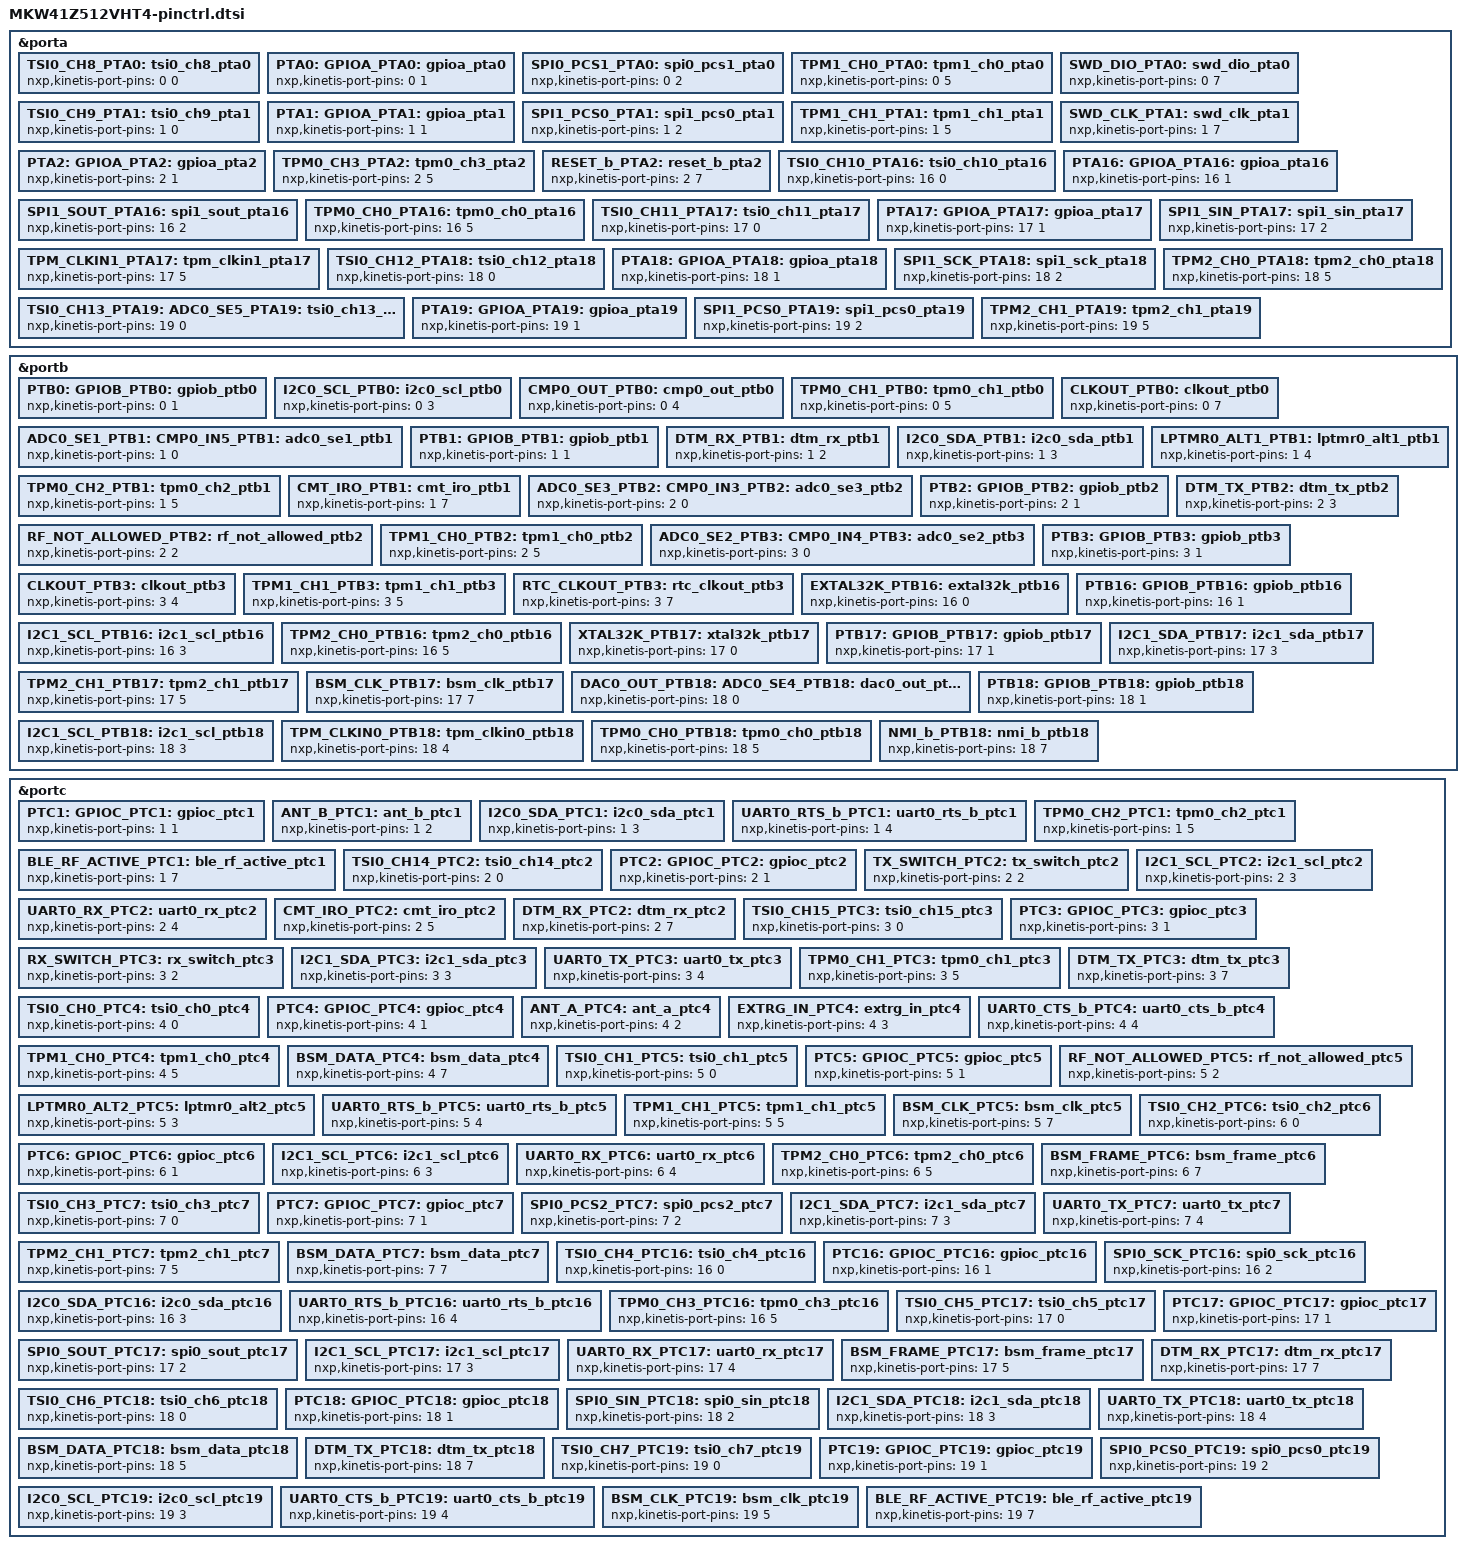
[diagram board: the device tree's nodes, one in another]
/*
 * NOTE: Autogenerated file by kinetis_signal2dts.py
 *       for MKW41Z512VHT4/signal_configuration.xml
 *
 * SPDX-License-Identifier: Apache-2.0
 */

/*
 * Pin nodes are of the form:
 *
 *	<SIGNAL[0..n]>: <signal[0]> {
 *		nxp,kinetis-port-pins = < PIN PCR[MUX] >;
 *	};
 */

&porta {
	TSI0_CH8_PTA0: tsi0_ch8_pta0 {
		nxp,kinetis-port-pins = < 0 0 >;
	};
	PTA0: GPIOA_PTA0: gpioa_pta0 {
		nxp,kinetis-port-pins = < 0 1 >;
	};
	SPI0_PCS1_PTA0: spi0_pcs1_pta0 {
		nxp,kinetis-port-pins = < 0 2 >;
	};
	TPM1_CH0_PTA0: tpm1_ch0_pta0 {
		nxp,kinetis-port-pins = < 0 5 >;
	};
	SWD_DIO_PTA0: swd_dio_pta0 {
		nxp,kinetis-port-pins = < 0 7 >;
	};
	TSI0_CH9_PTA1: tsi0_ch9_pta1 {
		nxp,kinetis-port-pins = < 1 0 >;
	};
	PTA1: GPIOA_PTA1: gpioa_pta1 {
		nxp,kinetis-port-pins = < 1 1 >;
	};
	SPI1_PCS0_PTA1: spi1_pcs0_pta1 {
		nxp,kinetis-port-pins = < 1 2 >;
	};
	TPM1_CH1_PTA1: tpm1_ch1_pta1 {
		nxp,kinetis-port-pins = < 1 5 >;
	};
	SWD_CLK_PTA1: swd_clk_pta1 {
		nxp,kinetis-port-pins = < 1 7 >;
	};
	PTA2: GPIOA_PTA2: gpioa_pta2 {
		nxp,kinetis-port-pins = < 2 1 >;
	};
	TPM0_CH3_PTA2: tpm0_ch3_pta2 {
		nxp,kinetis-port-pins = < 2 5 >;
	};
	RESET_b_PTA2: reset_b_pta2 {
		nxp,kinetis-port-pins = < 2 7 >;
	};
	TSI0_CH10_PTA16: tsi0_ch10_pta16 {
		nxp,kinetis-port-pins = < 16 0 >;
	};
	PTA16: GPIOA_PTA16: LLWU_P4_PTA16: gpioa_pta16 {
		nxp,kinetis-port-pins = < 16 1 >;
	};
	SPI1_SOUT_PTA16: spi1_sout_pta16 {
		nxp,kinetis-port-pins = < 16 2 >;
	};
	TPM0_CH0_PTA16: tpm0_ch0_pta16 {
		nxp,kinetis-port-pins = < 16 5 >;
	};
	TSI0_CH11_PTA17: tsi0_ch11_pta17 {
		nxp,kinetis-port-pins = < 17 0 >;
	};
	PTA17: GPIOA_PTA17: LLWU_P5_PTA17: RF_RESET_PTA17: gpioa_pta17 {
		nxp,kinetis-port-pins = < 17 1 >;
	};
	SPI1_SIN_PTA17: spi1_sin_pta17 {
		nxp,kinetis-port-pins = < 17 2 >;
	};
	TPM_CLKIN1_PTA17: tpm_clkin1_pta17 {
		nxp,kinetis-port-pins = < 17 5 >;
	};
	TSI0_CH12_PTA18: tsi0_ch12_pta18 {
		nxp,kinetis-port-pins = < 18 0 >;
	};
	PTA18: GPIOA_PTA18: LLWU_P6_PTA18: gpioa_pta18 {
		nxp,kinetis-port-pins = < 18 1 >;
	};
	SPI1_SCK_PTA18: spi1_sck_pta18 {
		nxp,kinetis-port-pins = < 18 2 >;
	};
	TPM2_CH0_PTA18: tpm2_ch0_pta18 {
		nxp,kinetis-port-pins = < 18 5 >;
	};
	TSI0_CH13_PTA19: ADC0_SE5_PTA19: tsi0_ch13_pta19 {
		nxp,kinetis-port-pins = < 19 0 >;
	};
	PTA19: GPIOA_PTA19: LLWU_P7_PTA19: gpioa_pta19 {
		nxp,kinetis-port-pins = < 19 1 >;
	};
	SPI1_PCS0_PTA19: spi1_pcs0_pta19 {
		nxp,kinetis-port-pins = < 19 2 >;
	};
	TPM2_CH1_PTA19: tpm2_ch1_pta19 {
		nxp,kinetis-port-pins = < 19 5 >;
	};
};

&portb {
	PTB0: GPIOB_PTB0: LLWU_P8_PTB0: XTAL_OUT_EN_PTB0: gpiob_ptb0 {
		nxp,kinetis-port-pins = < 0 1 >;
	};
	I2C0_SCL_PTB0: i2c0_scl_ptb0 {
		nxp,kinetis-port-pins = < 0 3 >;
	};
	CMP0_OUT_PTB0: cmp0_out_ptb0 {
		nxp,kinetis-port-pins = < 0 4 >;
	};
	TPM0_CH1_PTB0: tpm0_ch1_ptb0 {
		nxp,kinetis-port-pins = < 0 5 >;
	};
	CLKOUT_PTB0: clkout_ptb0 {
		nxp,kinetis-port-pins = < 0 7 >;
	};
	ADC0_SE1_PTB1: CMP0_IN5_PTB1: adc0_se1_ptb1 {
		nxp,kinetis-port-pins = < 1 0 >;
	};
	PTB1: GPIOB_PTB1: gpiob_ptb1 {
		nxp,kinetis-port-pins = < 1 1 >;
	};
	DTM_RX_PTB1: dtm_rx_ptb1 {
		nxp,kinetis-port-pins = < 1 2 >;
	};
	I2C0_SDA_PTB1: i2c0_sda_ptb1 {
		nxp,kinetis-port-pins = < 1 3 >;
	};
	LPTMR0_ALT1_PTB1: lptmr0_alt1_ptb1 {
		nxp,kinetis-port-pins = < 1 4 >;
	};
	TPM0_CH2_PTB1: tpm0_ch2_ptb1 {
		nxp,kinetis-port-pins = < 1 5 >;
	};
	CMT_IRO_PTB1: cmt_iro_ptb1 {
		nxp,kinetis-port-pins = < 1 7 >;
	};
	ADC0_SE3_PTB2: CMP0_IN3_PTB2: adc0_se3_ptb2 {
		nxp,kinetis-port-pins = < 2 0 >;
	};
	PTB2: GPIOB_PTB2: gpiob_ptb2 {
		nxp,kinetis-port-pins = < 2 1 >;
	};
	RF_NOT_ALLOWED_PTB2: rf_not_allowed_ptb2 {
		nxp,kinetis-port-pins = < 2 2 >;
	};
	DTM_TX_PTB2: dtm_tx_ptb2 {
		nxp,kinetis-port-pins = < 2 3 >;
	};
	TPM1_CH0_PTB2: tpm1_ch0_ptb2 {
		nxp,kinetis-port-pins = < 2 5 >;
	};
	ADC0_SE2_PTB3: CMP0_IN4_PTB3: adc0_se2_ptb3 {
		nxp,kinetis-port-pins = < 3 0 >;
	};
	PTB3: GPIOB_PTB3: gpiob_ptb3 {
		nxp,kinetis-port-pins = < 3 1 >;
	};
	CLKOUT_PTB3: clkout_ptb3 {
		nxp,kinetis-port-pins = < 3 4 >;
	};
	TPM1_CH1_PTB3: tpm1_ch1_ptb3 {
		nxp,kinetis-port-pins = < 3 5 >;
	};
	RTC_CLKOUT_PTB3: rtc_clkout_ptb3 {
		nxp,kinetis-port-pins = < 3 7 >;
	};
	EXTAL32K_PTB16: extal32k_ptb16 {
		nxp,kinetis-port-pins = < 16 0 >;
	};
	PTB16: GPIOB_PTB16: gpiob_ptb16 {
		nxp,kinetis-port-pins = < 16 1 >;
	};
	I2C1_SCL_PTB16: i2c1_scl_ptb16 {
		nxp,kinetis-port-pins = < 16 3 >;
	};
	TPM2_CH0_PTB16: tpm2_ch0_ptb16 {
		nxp,kinetis-port-pins = < 16 5 >;
	};
	XTAL32K_PTB17: xtal32k_ptb17 {
		nxp,kinetis-port-pins = < 17 0 >;
	};
	PTB17: GPIOB_PTB17: gpiob_ptb17 {
		nxp,kinetis-port-pins = < 17 1 >;
	};
	I2C1_SDA_PTB17: i2c1_sda_ptb17 {
		nxp,kinetis-port-pins = < 17 3 >;
	};
	TPM2_CH1_PTB17: tpm2_ch1_ptb17 {
		nxp,kinetis-port-pins = < 17 5 >;
	};
	BSM_CLK_PTB17: bsm_clk_ptb17 {
		nxp,kinetis-port-pins = < 17 7 >;
	};
	DAC0_OUT_PTB18: ADC0_SE4_PTB18: CMP0_IN2_PTB18: dac0_out_ptb18 {
		nxp,kinetis-port-pins = < 18 0 >;
	};
	PTB18: GPIOB_PTB18: gpiob_ptb18 {
		nxp,kinetis-port-pins = < 18 1 >;
	};
	I2C1_SCL_PTB18: i2c1_scl_ptb18 {
		nxp,kinetis-port-pins = < 18 3 >;
	};
	TPM_CLKIN0_PTB18: tpm_clkin0_ptb18 {
		nxp,kinetis-port-pins = < 18 4 >;
	};
	TPM0_CH0_PTB18: tpm0_ch0_ptb18 {
		nxp,kinetis-port-pins = < 18 5 >;
	};
	NMI_b_PTB18: nmi_b_ptb18 {
		nxp,kinetis-port-pins = < 18 7 >;
	};
};

&portc {
	PTC1: GPIOC_PTC1: gpioc_ptc1 {
		nxp,kinetis-port-pins = < 1 1 >;
	};
	ANT_B_PTC1: ant_b_ptc1 {
		nxp,kinetis-port-pins = < 1 2 >;
	};
	I2C0_SDA_PTC1: i2c0_sda_ptc1 {
		nxp,kinetis-port-pins = < 1 3 >;
	};
	UART0_RTS_b_PTC1: uart0_rts_b_ptc1 {
		nxp,kinetis-port-pins = < 1 4 >;
	};
	TPM0_CH2_PTC1: tpm0_ch2_ptc1 {
		nxp,kinetis-port-pins = < 1 5 >;
	};
	BLE_RF_ACTIVE_PTC1: ble_rf_active_ptc1 {
		nxp,kinetis-port-pins = < 1 7 >;
	};
	TSI0_CH14_PTC2: tsi0_ch14_ptc2 {
		nxp,kinetis-port-pins = < 2 0 >;
	};
	PTC2: GPIOC_PTC2: LLWU_P10_PTC2: gpioc_ptc2 {
		nxp,kinetis-port-pins = < 2 1 >;
	};
	TX_SWITCH_PTC2: tx_switch_ptc2 {
		nxp,kinetis-port-pins = < 2 2 >;
	};
	I2C1_SCL_PTC2: i2c1_scl_ptc2 {
		nxp,kinetis-port-pins = < 2 3 >;
	};
	UART0_RX_PTC2: uart0_rx_ptc2 {
		nxp,kinetis-port-pins = < 2 4 >;
	};
	CMT_IRO_PTC2: cmt_iro_ptc2 {
		nxp,kinetis-port-pins = < 2 5 >;
	};
	DTM_RX_PTC2: dtm_rx_ptc2 {
		nxp,kinetis-port-pins = < 2 7 >;
	};
	TSI0_CH15_PTC3: tsi0_ch15_ptc3 {
		nxp,kinetis-port-pins = < 3 0 >;
	};
	PTC3: GPIOC_PTC3: LLWU_P11_PTC3: gpioc_ptc3 {
		nxp,kinetis-port-pins = < 3 1 >;
	};
	RX_SWITCH_PTC3: rx_switch_ptc3 {
		nxp,kinetis-port-pins = < 3 2 >;
	};
	I2C1_SDA_PTC3: i2c1_sda_ptc3 {
		nxp,kinetis-port-pins = < 3 3 >;
	};
	UART0_TX_PTC3: uart0_tx_ptc3 {
		nxp,kinetis-port-pins = < 3 4 >;
	};
	TPM0_CH1_PTC3: tpm0_ch1_ptc3 {
		nxp,kinetis-port-pins = < 3 5 >;
	};
	DTM_TX_PTC3: dtm_tx_ptc3 {
		nxp,kinetis-port-pins = < 3 7 >;
	};
	TSI0_CH0_PTC4: tsi0_ch0_ptc4 {
		nxp,kinetis-port-pins = < 4 0 >;
	};
	PTC4: GPIOC_PTC4: LLWU_P12_PTC4: gpioc_ptc4 {
		nxp,kinetis-port-pins = < 4 1 >;
	};
	ANT_A_PTC4: ant_a_ptc4 {
		nxp,kinetis-port-pins = < 4 2 >;
	};
	EXTRG_IN_PTC4: extrg_in_ptc4 {
		nxp,kinetis-port-pins = < 4 3 >;
	};
	UART0_CTS_b_PTC4: uart0_cts_b_ptc4 {
		nxp,kinetis-port-pins = < 4 4 >;
	};
	TPM1_CH0_PTC4: tpm1_ch0_ptc4 {
		nxp,kinetis-port-pins = < 4 5 >;
	};
	BSM_DATA_PTC4: bsm_data_ptc4 {
		nxp,kinetis-port-pins = < 4 7 >;
	};
	TSI0_CH1_PTC5: tsi0_ch1_ptc5 {
		nxp,kinetis-port-pins = < 5 0 >;
	};
	PTC5: GPIOC_PTC5: LLWU_P13_PTC5: gpioc_ptc5 {
		nxp,kinetis-port-pins = < 5 1 >;
	};
	RF_NOT_ALLOWED_PTC5: rf_not_allowed_ptc5 {
		nxp,kinetis-port-pins = < 5 2 >;
	};
	LPTMR0_ALT2_PTC5: lptmr0_alt2_ptc5 {
		nxp,kinetis-port-pins = < 5 3 >;
	};
	UART0_RTS_b_PTC5: uart0_rts_b_ptc5 {
		nxp,kinetis-port-pins = < 5 4 >;
	};
	TPM1_CH1_PTC5: tpm1_ch1_ptc5 {
		nxp,kinetis-port-pins = < 5 5 >;
	};
	BSM_CLK_PTC5: bsm_clk_ptc5 {
		nxp,kinetis-port-pins = < 5 7 >;
	};
	TSI0_CH2_PTC6: tsi0_ch2_ptc6 {
		nxp,kinetis-port-pins = < 6 0 >;
	};
	PTC6: GPIOC_PTC6: LLWU_P14_PTC6: XTAL_OUT_EN_PTC6: gpioc_ptc6 {
		nxp,kinetis-port-pins = < 6 1 >;
	};
	I2C1_SCL_PTC6: i2c1_scl_ptc6 {
		nxp,kinetis-port-pins = < 6 3 >;
	};
	UART0_RX_PTC6: uart0_rx_ptc6 {
		nxp,kinetis-port-pins = < 6 4 >;
	};
	TPM2_CH0_PTC6: tpm2_ch0_ptc6 {
		nxp,kinetis-port-pins = < 6 5 >;
	};
	BSM_FRAME_PTC6: bsm_frame_ptc6 {
		nxp,kinetis-port-pins = < 6 7 >;
	};
	TSI0_CH3_PTC7: tsi0_ch3_ptc7 {
		nxp,kinetis-port-pins = < 7 0 >;
	};
	PTC7: GPIOC_PTC7: LLWU_P15_PTC7: gpioc_ptc7 {
		nxp,kinetis-port-pins = < 7 1 >;
	};
	SPI0_PCS2_PTC7: spi0_pcs2_ptc7 {
		nxp,kinetis-port-pins = < 7 2 >;
	};
	I2C1_SDA_PTC7: i2c1_sda_ptc7 {
		nxp,kinetis-port-pins = < 7 3 >;
	};
	UART0_TX_PTC7: uart0_tx_ptc7 {
		nxp,kinetis-port-pins = < 7 4 >;
	};
	TPM2_CH1_PTC7: tpm2_ch1_ptc7 {
		nxp,kinetis-port-pins = < 7 5 >;
	};
	BSM_DATA_PTC7: bsm_data_ptc7 {
		nxp,kinetis-port-pins = < 7 7 >;
	};
	TSI0_CH4_PTC16: tsi0_ch4_ptc16 {
		nxp,kinetis-port-pins = < 16 0 >;
	};
	PTC16: GPIOC_PTC16: LLWU_P0_PTC16: gpioc_ptc16 {
		nxp,kinetis-port-pins = < 16 1 >;
	};
	SPI0_SCK_PTC16: spi0_sck_ptc16 {
		nxp,kinetis-port-pins = < 16 2 >;
	};
	I2C0_SDA_PTC16: i2c0_sda_ptc16 {
		nxp,kinetis-port-pins = < 16 3 >;
	};
	UART0_RTS_b_PTC16: uart0_rts_b_ptc16 {
		nxp,kinetis-port-pins = < 16 4 >;
	};
	TPM0_CH3_PTC16: tpm0_ch3_ptc16 {
		nxp,kinetis-port-pins = < 16 5 >;
	};
	TSI0_CH5_PTC17: tsi0_ch5_ptc17 {
		nxp,kinetis-port-pins = < 17 0 >;
	};
	PTC17: GPIOC_PTC17: LLWU_P1_PTC17: gpioc_ptc17 {
		nxp,kinetis-port-pins = < 17 1 >;
	};
	SPI0_SOUT_PTC17: spi0_sout_ptc17 {
		nxp,kinetis-port-pins = < 17 2 >;
	};
	I2C1_SCL_PTC17: i2c1_scl_ptc17 {
		nxp,kinetis-port-pins = < 17 3 >;
	};
	UART0_RX_PTC17: uart0_rx_ptc17 {
		nxp,kinetis-port-pins = < 17 4 >;
	};
	BSM_FRAME_PTC17: bsm_frame_ptc17 {
		nxp,kinetis-port-pins = < 17 5 >;
	};
	DTM_RX_PTC17: dtm_rx_ptc17 {
		nxp,kinetis-port-pins = < 17 7 >;
	};
	TSI0_CH6_PTC18: tsi0_ch6_ptc18 {
		nxp,kinetis-port-pins = < 18 0 >;
	};
	PTC18: GPIOC_PTC18: LLWU_P2_PTC18: gpioc_ptc18 {
		nxp,kinetis-port-pins = < 18 1 >;
	};
	SPI0_SIN_PTC18: spi0_sin_ptc18 {
		nxp,kinetis-port-pins = < 18 2 >;
	};
	I2C1_SDA_PTC18: i2c1_sda_ptc18 {
		nxp,kinetis-port-pins = < 18 3 >;
	};
	UART0_TX_PTC18: uart0_tx_ptc18 {
		nxp,kinetis-port-pins = < 18 4 >;
	};
	BSM_DATA_PTC18: bsm_data_ptc18 {
		nxp,kinetis-port-pins = < 18 5 >;
	};
	DTM_TX_PTC18: dtm_tx_ptc18 {
		nxp,kinetis-port-pins = < 18 7 >;
	};
	TSI0_CH7_PTC19: tsi0_ch7_ptc19 {
		nxp,kinetis-port-pins = < 19 0 >;
	};
	PTC19: GPIOC_PTC19: LLWU_P3_PTC19: gpioc_ptc19 {
		nxp,kinetis-port-pins = < 19 1 >;
	};
	SPI0_PCS0_PTC19: spi0_pcs0_ptc19 {
		nxp,kinetis-port-pins = < 19 2 >;
	};
	I2C0_SCL_PTC19: i2c0_scl_ptc19 {
		nxp,kinetis-port-pins = < 19 3 >;
	};
	UART0_CTS_b_PTC19: uart0_cts_b_ptc19 {
		nxp,kinetis-port-pins = < 19 4 >;
	};
	BSM_CLK_PTC19: bsm_clk_ptc19 {
		nxp,kinetis-port-pins = < 19 5 >;
	};
	BLE_RF_ACTIVE_PTC19: ble_rf_active_ptc19 {
		nxp,kinetis-port-pins = < 19 7 >;
	};
};

